VERSION ""
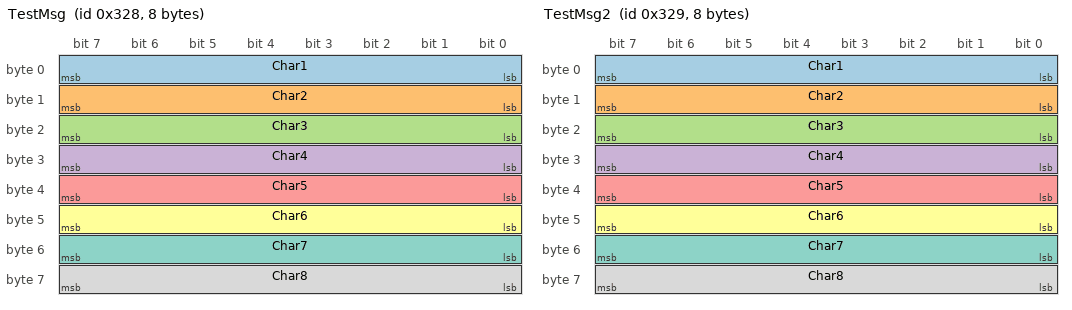
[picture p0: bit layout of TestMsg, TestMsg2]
BO_ 808 TestMsg: 8 Vector__XXX
SG_ Char1 : 0|8@1+ (1,0) [0|256] "none" Vector__XXX
SG_ Char2 : 8|8@1+ (1,0) [0|256] "none" Vector__XXX
SG_ Char3 : 16|8@1+ (1,0) [0|256] "none" Vector__XXX
SG_ Char4 : 24|8@1+ (1,0) [0|256] "none" Vector__XXX
SG_ Char5 : 32|8@1+ (1,0) [0|256] "none" Vector__XXX
SG_ Char6 : 40|8@1+ (1,0) [0|256] "none" Vector__XXX
SG_ Char7 : 48|8@1+ (1,0) [0|256] "none" Vector__XXX
SG_ Char8 : 56|8@1+ (1,0) [0|256] "none" Vector__XXX

BO_ 809 TestMsg2: 8 Vector__XXX
SG_ Char1 : 0|8@1+ (1,0) [0|256] "none" Vector__XXX
SG_ Char2 : 8|8@1+ (1,0) [0|256] "none" Vector__XXX
SG_ Char3 : 16|8@1+ (1,0) [0|256] "none" Vector__XXX
SG_ Char4 : 24|8@1+ (1,0) [0|256] "none" Vector__XXX
SG_ Char5 : 32|8@1+ (1,0) [0|256] "none" Vector__XXX
SG_ Char6 : 40|8@1+ (1,0) [0|256] "none" Vector__XXX
SG_ Char7 : 48|8@1+ (1,0) [0|256] "none" Vector__XXX
SG_ Char8 : 56|8@1+ (1,0) [0|256] "none" Vector__XXX

CM_ BO_ 808 "Test Message 1 Content";
CM_ SG_ 808 Char1 "Character 1";
CM_ BO_ 809 "Test Message 2 Content";
BA_DEF_ SG_  "SPN" INT 0 524287;
BA_DEF_ BO_  "VFrameFormat" ENUM  "StandardCAN","ExtendedCAN","reserved","J1939PG";
BA_DEF_  "DatabaseVersion" STRING ;
BA_DEF_  "BusType" STRING ;
BA_DEF_  "ProtocolType" STRING ;
BA_DEF_  "DatabaseCompiler" STRING ;
BA_DEF_DEF_  "SPN" 0;
BA_DEF_DEF_  "VFrameFormat" "J1939PG";
BA_DEF_DEF_  "DatabaseVersion" "DEMO PLUS";
BA_DEF_DEF_  "BusType" "";
BA_DEF_DEF_  "ProtocolType" "";
BA_DEF_DEF_  "DatabaseCompiler" "";
BA_ "ProtocolType" "J1939";
BA_ "BusType" "CAN";
BA_ "DatabaseCompiler" "CSS ELECTRONICS (WWW.CSSELECTRONICS.COM)";
BA_ "DatabaseVersion" "1.0.0";
BA_ "SPN" SG_ 2364540158 EngineSpeed 190;
BA_ "SPN" SG_ 2566844926 WheelBasedVehicleSpeed 84;
